# TM4C129ENCPDT register map
File version: 1.0
CPU: CORTEX_M4 1.0, other endian, MPU, FPU, 3 interrupt priority bits
Registers are 32-bit, read-write, reset 0x0 unless marked. A register's access mark holds for its fields unless they carry their own. Offsets are from the block's base; [hi:lo] are bit positions.

## TIMER0 — Timer register offsets
Base 0x40030000
Same registers: TIMER1 0x40031000, TIMER2 0x40032000, TIMER3 0x40033000, TIMER4 0x40034000, TIMER5 0x40035000, TIMER6 0x400E0000, TIMER7 0x400E1000
0x00 TIMER_CFG — GPTM Configuration
  [2:0] TIMER_CFG — [2:0] GPTM Configuration
    0=TIMER_CFG_32_BIT_TIMER (For a 16/32-bit timer, this value selects the 32-bit timer configuration); 1=TIMER_CFG_32_BIT_RTC (For a 16/32-bit timer, this value selects the 32-bit real-time clock (RTC) counter configuration); 4=TIMER_CFG_16_BIT (For a 16/32-bit timer, this value selects the 16-bit timer configuration)
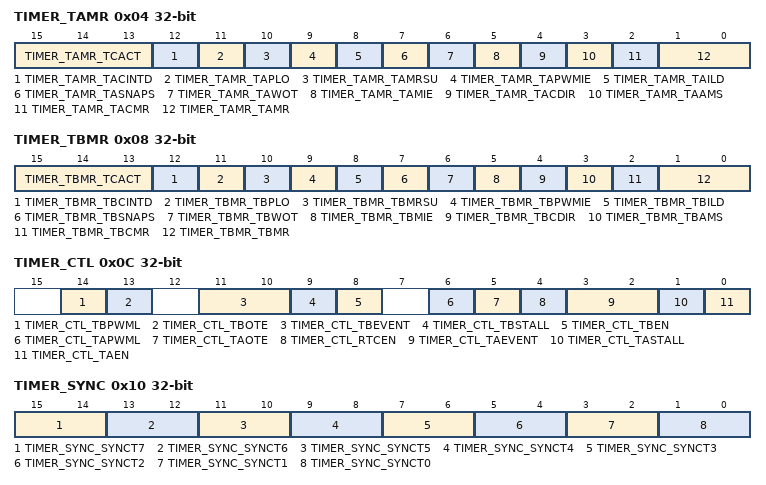
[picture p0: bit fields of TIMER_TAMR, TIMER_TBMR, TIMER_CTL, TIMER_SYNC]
0x04 TIMER_TAMR — GPTM Timer A Mode
  [15:13] TIMER_TAMR_TCACT — [15:13] Timer Compare Action Select
    0=TIMER_TAMR_TCACT_NONE (Disable compare operations); 0x2000=TIMER_TAMR_TCACT_TOGGLE (Toggle State on Time-Out); 0x4000=TIMER_TAMR_TCACT_CLRTO (Clear CCP on Time-Out); 0x6000=TIMER_TAMR_TCACT_SETTO (Set CCP on Time-Out); 0x8000=TIMER_TAMR_TCACT_SETTOGTO (Set CCP immediately and toggle on Time-Out); 0xA000=TIMER_TAMR_TCACT_CLRTOGTO (Clear CCP immediately and toggle on Time-Out); 0xC000=TIMER_TAMR_TCACT_SETCLRTO (Set CCP immediately and clear on Time-Out); 0xE000=TIMER_TAMR_TCACT_CLRSETTO (Clear CCP immediately and set on Time-Out)
  [12] TIMER_TAMR_TACINTD — [12:12] One-shot/Periodic Interrupt Disable
  [11] TIMER_TAMR_TAPLO — [11:11] GPTM Timer A PWM Legacy Operation
  [10] TIMER_TAMR_TAMRSU — [10:10] GPTM Timer A Match Register Update
  [9] TIMER_TAMR_TAPWMIE — [9:9] GPTM Timer A PWM Interrupt Enable
  [8] TIMER_TAMR_TAILD — [8:8] GPTM Timer A Interval Load Write
  [7] TIMER_TAMR_TASNAPS — [7:7] GPTM Timer A Snap-Shot Mode
  [6] TIMER_TAMR_TAWOT — [6:6] GPTM Timer A Wait-on-Trigger
  [5] TIMER_TAMR_TAMIE — [5:5] GPTM Timer A Match Interrupt Enable
  [4] TIMER_TAMR_TACDIR — [4:4] GPTM Timer A Count Direction
  [3] TIMER_TAMR_TAAMS — [3:3] GPTM Timer A Alternate Mode Select
  [2] TIMER_TAMR_TACMR — [2:2] GPTM Timer A Capture Mode
  [1:0] TIMER_TAMR_TAMR — [1:0] GPTM Timer A Mode
    1=TIMER_TAMR_TAMR_1_SHOT (One-Shot Timer mode); 2=TIMER_TAMR_TAMR_PERIOD (Periodic Timer mode); 3=TIMER_TAMR_TAMR_CAP (Capture mode)
0x08 TIMER_TBMR — GPTM Timer B Mode
  [15:13] TIMER_TBMR_TCACT — [15:13] Timer Compare Action Select
    0=TIMER_TBMR_TCACT_NONE (Disable compare operations); 0x2000=TIMER_TBMR_TCACT_TOGGLE (Toggle State on Time-Out); 0x4000=TIMER_TBMR_TCACT_CLRTO (Clear CCP on Time-Out); 0x6000=TIMER_TBMR_TCACT_SETTO (Set CCP on Time-Out); 0x8000=TIMER_TBMR_TCACT_SETTOGTO (Set CCP immediately and toggle on Time-Out); 0xA000=TIMER_TBMR_TCACT_CLRTOGTO (Clear CCP immediately and toggle on Time-Out); 0xC000=TIMER_TBMR_TCACT_SETCLRTO (Set CCP immediately and clear on Time-Out); 0xE000=TIMER_TBMR_TCACT_CLRSETTO (Clear CCP immediately and set on Time-Out)
  [12] TIMER_TBMR_TBCINTD — [12:12] One-Shot/Periodic Interrupt Disable
  [11] TIMER_TBMR_TBPLO — [11:11] GPTM Timer B PWM Legacy Operation
  [10] TIMER_TBMR_TBMRSU — [10:10] GPTM Timer B Match Register Update
  [9] TIMER_TBMR_TBPWMIE — [9:9] GPTM Timer B PWM Interrupt Enable
  [8] TIMER_TBMR_TBILD — [8:8] GPTM Timer B Interval Load Write
  [7] TIMER_TBMR_TBSNAPS — [7:7] GPTM Timer B Snap-Shot Mode
  [6] TIMER_TBMR_TBWOT — [6:6] GPTM Timer B Wait-on-Trigger
  [5] TIMER_TBMR_TBMIE — [5:5] GPTM Timer B Match Interrupt Enable
  [4] TIMER_TBMR_TBCDIR — [4:4] GPTM Timer B Count Direction
  [3] TIMER_TBMR_TBAMS — [3:3] GPTM Timer B Alternate Mode Select
  [2] TIMER_TBMR_TBCMR — [2:2] GPTM Timer B Capture Mode
  [1:0] TIMER_TBMR_TBMR — [1:0] GPTM Timer B Mode
    1=TIMER_TBMR_TBMR_1_SHOT (One-Shot Timer mode); 2=TIMER_TBMR_TBMR_PERIOD (Periodic Timer mode); 3=TIMER_TBMR_TBMR_CAP (Capture mode)
0x0C TIMER_CTL — GPTM Control
  [14] TIMER_CTL_TBPWML — [14:14] GPTM Timer B PWM Output Level
  [13] TIMER_CTL_TBOTE — [13:13] GPTM Timer B Output Trigger Enable
  [11:10] TIMER_CTL_TBEVENT — [11:10] GPTM Timer B Event Mode
    0=TIMER_CTL_TBEVENT_POS (Positive edge); 0x400=TIMER_CTL_TBEVENT_NEG (Negative edge); 0xC00=TIMER_CTL_TBEVENT_BOTH (Both edges)
  [9] TIMER_CTL_TBSTALL — [9:9] GPTM Timer B Stall Enable
  [8] TIMER_CTL_TBEN — [8:8] GPTM Timer B Enable
  [6] TIMER_CTL_TAPWML — [6:6] GPTM Timer A PWM Output Level
  [5] TIMER_CTL_TAOTE — [5:5] GPTM Timer A Output Trigger Enable
  [4] TIMER_CTL_RTCEN — [4:4] GPTM RTC Stall Enable
  [3:2] TIMER_CTL_TAEVENT — [3:2] GPTM Timer A Event Mode
    0=TIMER_CTL_TAEVENT_POS (Positive edge); 4=TIMER_CTL_TAEVENT_NEG (Negative edge); 12=TIMER_CTL_TAEVENT_BOTH (Both edges)
  [1] TIMER_CTL_TASTALL — [1:1] GPTM Timer A Stall Enable
  [0] TIMER_CTL_TAEN — [0:0] GPTM Timer A Enable
0x10 TIMER_SYNC — GPTM Synchronize
  [15:14] TIMER_SYNC_SYNCT7 — [15:14] Synchronize GPTM Timer 7
    0=TIMER_SYNC_SYNCT7_NONE (GPT7 is not affected); 0x4000=TIMER_SYNC_SYNCT7_TA (A timeout event for Timer A of GPTM7 is triggered); 0x8000=TIMER_SYNC_SYNCT7_TB (A timeout event for Timer B of GPTM7 is triggered); 0xC000=TIMER_SYNC_SYNCT7_TATB (A timeout event for both Timer A and Timer B of GPTM7 is triggered)
  [13:12] TIMER_SYNC_SYNCT6 — [13:12] Synchronize GPTM Timer 6
    0=TIMER_SYNC_SYNCT6_NONE (GPTM6 is not affected); 0x1000=TIMER_SYNC_SYNCT6_TA (A timeout event for Timer A of GPTM6 is triggered); 0x2000=TIMER_SYNC_SYNCT6_TB (A timeout event for Timer B of GPTM6 is triggered); 0x3000=TIMER_SYNC_SYNCT6_TATB (A timeout event for both Timer A and Timer B of GPTM6 is triggered)
  [11:10] TIMER_SYNC_SYNCT5 — [11:10] Synchronize GPTM Timer 5
    0=TIMER_SYNC_SYNCT5_NONE (GPTM5 is not affected); 0x400=TIMER_SYNC_SYNCT5_TA (A timeout event for Timer A of GPTM5 is triggered); 0x800=TIMER_SYNC_SYNCT5_TB (A timeout event for Timer B of GPTM5 is triggered); 0xC00=TIMER_SYNC_SYNCT5_TATB (A timeout event for both Timer A and Timer B of GPTM5 is triggered)
  [9:8] TIMER_SYNC_SYNCT4 — [9:8] Synchronize GPTM Timer 4
    0=TIMER_SYNC_SYNCT4_NONE (GPTM4 is not affected); 0x100=TIMER_SYNC_SYNCT4_TA (A timeout event for Timer A of GPTM4 is triggered); 0x200=TIMER_SYNC_SYNCT4_TB (A timeout event for Timer B of GPTM4 is triggered); 0x300=TIMER_SYNC_SYNCT4_TATB (A timeout event for both Timer A and Timer B of GPTM4 is triggered)
  [7:6] TIMER_SYNC_SYNCT3 — [7:6] Synchronize GPTM Timer 3
    0=TIMER_SYNC_SYNCT3_NONE (GPTM3 is not affected); 64=TIMER_SYNC_SYNCT3_TA (A timeout event for Timer A of GPTM3 is triggered); 128=TIMER_SYNC_SYNCT3_TB (A timeout event for Timer B of GPTM3 is triggered); 192=TIMER_SYNC_SYNCT3_TATB (A timeout event for both Timer A and Timer B of GPTM3 is triggered)
  [5:4] TIMER_SYNC_SYNCT2 — [5:4] Synchronize GPTM Timer 2
    0=TIMER_SYNC_SYNCT2_NONE (GPTM2 is not affected); 16=TIMER_SYNC_SYNCT2_TA (A timeout event for Timer A of GPTM2 is triggered); 32=TIMER_SYNC_SYNCT2_TB (A timeout event for Timer B of GPTM2 is triggered); 48=TIMER_SYNC_SYNCT2_TATB (A timeout event for both Timer A and Timer B of GPTM2 is triggered)
  [3:2] TIMER_SYNC_SYNCT1 — [3:2] Synchronize GPTM Timer 1
    0=TIMER_SYNC_SYNCT1_NONE (GPTM1 is not affected); 4=TIMER_SYNC_SYNCT1_TA (A timeout event for Timer A of GPTM1 is triggered); 8=TIMER_SYNC_SYNCT1_TB (A timeout event for Timer B of GPTM1 is triggered); 12=TIMER_SYNC_SYNCT1_TATB (A timeout event for both Timer A and Timer B of GPTM1 is triggered)
  [1:0] TIMER_SYNC_SYNCT0 — [1:0] Synchronize GPTM Timer 0
    0=TIMER_SYNC_SYNCT0_NONE (GPTM0 is not affected); 1=TIMER_SYNC_SYNCT0_TA (A timeout event for Timer A of GPTM0 is triggered); 2=TIMER_SYNC_SYNCT0_TB (A timeout event for Timer B of GPTM0 is triggered); 3=TIMER_SYNC_SYNCT0_TATB (A timeout event for both Timer A and Timer B of GPTM0 is triggered)
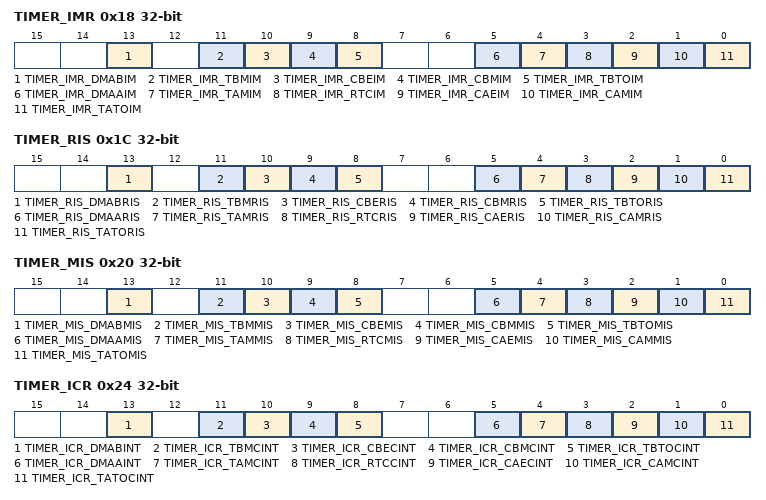
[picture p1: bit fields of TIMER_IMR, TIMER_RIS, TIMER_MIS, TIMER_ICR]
0x18 TIMER_IMR — GPTM Interrupt Mask
  [13] TIMER_IMR_DMABIM — [13:13] GPTM Timer B DMA Done Interrupt Mask
  [11] TIMER_IMR_TBMIM — [11:11] GPTM Timer B Match Interrupt Mask
  [10] TIMER_IMR_CBEIM — [10:10] GPTM Timer B Capture Mode Event Interrupt Mask
  [9] TIMER_IMR_CBMIM — [9:9] GPTM Timer B Capture Mode Match Interrupt Mask
  [8] TIMER_IMR_TBTOIM — [8:8] GPTM Timer B Time-Out Interrupt Mask
  [5] TIMER_IMR_DMAAIM — [5:5] GPTM Timer A DMA Done Interrupt Mask
  [4] TIMER_IMR_TAMIM — [4:4] GPTM Timer A Match Interrupt Mask
  [3] TIMER_IMR_RTCIM — [3:3] GPTM RTC Interrupt Mask
  [2] TIMER_IMR_CAEIM — [2:2] GPTM Timer A Capture Mode Event Interrupt Mask
  [1] TIMER_IMR_CAMIM — [1:1] GPTM Timer A Capture Mode Match Interrupt Mask
  [0] TIMER_IMR_TATOIM — [0:0] GPTM Timer A Time-Out Interrupt Mask
0x1C TIMER_RIS — GPTM Raw Interrupt Status
  [13] TIMER_RIS_DMABRIS — [13:13] GPTM Timer B DMA Done Raw Interrupt Status
  [11] TIMER_RIS_TBMRIS — [11:11] GPTM Timer B Match Raw Interrupt
  [10] TIMER_RIS_CBERIS — [10:10] GPTM Timer B Capture Mode Event Raw Interrupt
  [9] TIMER_RIS_CBMRIS — [9:9] GPTM Timer B Capture Mode Match Raw Interrupt
  [8] TIMER_RIS_TBTORIS — [8:8] GPTM Timer B Time-Out Raw Interrupt
  [5] TIMER_RIS_DMAARIS — [5:5] GPTM Timer A DMA Done Raw Interrupt Status
  [4] TIMER_RIS_TAMRIS — [4:4] GPTM Timer A Match Raw Interrupt
  [3] TIMER_RIS_RTCRIS — [3:3] GPTM RTC Raw Interrupt
  [2] TIMER_RIS_CAERIS — [2:2] GPTM Timer A Capture Mode Event Raw Interrupt
  [1] TIMER_RIS_CAMRIS — [1:1] GPTM Timer A Capture Mode Match Raw Interrupt
  [0] TIMER_RIS_TATORIS — [0:0] GPTM Timer A Time-Out Raw Interrupt
0x20 TIMER_MIS — GPTM Masked Interrupt Status
  [13] TIMER_MIS_DMABMIS — [13:13] GPTM Timer B DMA Done Masked Interrupt
  [11] TIMER_MIS_TBMMIS — [11:11] GPTM Timer B Match Masked Interrupt
  [10] TIMER_MIS_CBEMIS — [10:10] GPTM Timer B Capture Mode Event Masked Interrupt
  [9] TIMER_MIS_CBMMIS — [9:9] GPTM Timer B Capture Mode Match Masked Interrupt
  [8] TIMER_MIS_TBTOMIS — [8:8] GPTM Timer B Time-Out Masked Interrupt
  [5] TIMER_MIS_DMAAMIS — [5:5] GPTM Timer A DMA Done Masked Interrupt
  [4] TIMER_MIS_TAMMIS — [4:4] GPTM Timer A Match Masked Interrupt
  [3] TIMER_MIS_RTCMIS — [3:3] GPTM RTC Masked Interrupt
  [2] TIMER_MIS_CAEMIS — [2:2] GPTM Timer A Capture Mode Event Masked Interrupt
  [1] TIMER_MIS_CAMMIS — [1:1] GPTM Timer A Capture Mode Match Masked Interrupt
  [0] TIMER_MIS_TATOMIS — [0:0] GPTM Timer A Time-Out Masked Interrupt
0x24 TIMER_ICR — GPTM Interrupt Clear
  [13] TIMER_ICR_DMABINT — [13:13] GPTM Timer B DMA Done Interrupt Clear
  [11] TIMER_ICR_TBMCINT — [11:11] GPTM Timer B Match Interrupt Clear
  [10] TIMER_ICR_CBECINT — [10:10] GPTM Timer B Capture Mode Event Interrupt Clear
  [9] TIMER_ICR_CBMCINT — [9:9] GPTM Timer B Capture Mode Match Interrupt Clear
  [8] TIMER_ICR_TBTOCINT — [8:8] GPTM Timer B Time-Out Interrupt Clear
  [5] TIMER_ICR_DMAAINT — [5:5] GPTM Timer A DMA Done Interrupt Clear
  [4] TIMER_ICR_TAMCINT — [4:4] GPTM Timer A Match Interrupt Clear
  [3] TIMER_ICR_RTCCINT — [3:3] GPTM RTC Interrupt Clear
  [2] TIMER_ICR_CAECINT — [2:2] GPTM Timer A Capture Mode Event Interrupt Clear
  [1] TIMER_ICR_CAMCINT — [1:1] GPTM Timer A Capture Mode Match Interrupt Clear
  [0] TIMER_ICR_TATOCINT — [0:0] GPTM Timer A Time-Out Raw Interrupt
0x28 TIMER_TAILR — GPTM Timer A Interval Load
  [31:0] TIMER_TAILR — [31:0] GPTM Timer A Interval Load Register
0x2C TIMER_TBILR — GPTM Timer B Interval Load
  [31:0] TIMER_TBILR — [31:0] GPTM Timer B Interval Load Register
0x30 TIMER_TAMATCHR — GPTM Timer A Match
  [31:0] TIMER_TAMATCHR_TAMR — [31:0] GPTM Timer A Match Register
0x34 TIMER_TBMATCHR — GPTM Timer B Match
  [31:0] TIMER_TBMATCHR_TBMR — [31:0] GPTM Timer B Match Register
0x38 TIMER_TAPR — GPTM Timer A Prescale
  [7:0] TIMER_TAPR_TAPSR — [7:0] GPTM Timer A Prescale
0x3C TIMER_TBPR — GPTM Timer B Prescale
  [7:0] TIMER_TBPR_TBPSR — [7:0] GPTM Timer B Prescale
0x40 TIMER_TAPMR — GPTM TimerA Prescale Match
  [7:0] TIMER_TAPMR_TAPSMR — [7:0] GPTM TimerA Prescale Match
0x44 TIMER_TBPMR — GPTM TimerB Prescale Match
  [7:0] TIMER_TBPMR_TBPSMR — [7:0] GPTM TimerB Prescale Match
0x48 TIMER_TAR — GPTM Timer A
  [31:0] TIMER_TAR — [31:0] GPTM Timer A Register
0x4C TIMER_TBR — GPTM Timer B
  [31:0] TIMER_TBR — [31:0] GPTM Timer B Register
0x50 TIMER_TAV — GPTM Timer A Value
  [31:0] TIMER_TAV — [31:0] GPTM Timer A Value
0x54 TIMER_TBV — GPTM Timer B Value
  [31:0] TIMER_TBV — [31:0] GPTM Timer B Value
0x58 TIMER_RTCPD — GPTM RTC Predivide
  [15:0] TIMER_RTCPD_RTCPD — [15:0] RTC Predivide Counter Value
0x5C TIMER_TAPS — GPTM Timer A Prescale Snapshot
  [15:0] TIMER_TAPS_PSS — [15:0] GPTM Timer A Prescaler Snapshot
0x60 TIMER_TBPS — GPTM Timer B Prescale Snapshot
  [15:0] TIMER_TBPS_PSS — [15:0] GPTM Timer A Prescaler Value
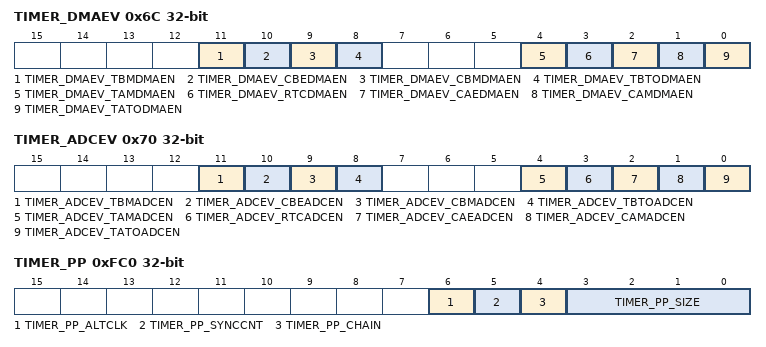
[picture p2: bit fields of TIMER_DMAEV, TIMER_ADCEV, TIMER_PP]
0x6C TIMER_DMAEV — GPTM DMA Event
  [11] TIMER_DMAEV_TBMDMAEN — [11:11] GPTM B Mode Match Event DMA Trigger Enable
  [10] TIMER_DMAEV_CBEDMAEN — [10:10] GPTM B Capture Event DMA Trigger Enable
  [9] TIMER_DMAEV_CBMDMAEN — [9:9] GPTM B Capture Match Event DMA Trigger Enable
  [8] TIMER_DMAEV_TBTODMAEN — [8:8] GPTM B Time-Out Event DMA Trigger Enable
  [4] TIMER_DMAEV_TAMDMAEN — [4:4] GPTM A Mode Match Event DMA Trigger Enable
  [3] TIMER_DMAEV_RTCDMAEN — [3:3] GPTM A RTC Match Event DMA Trigger Enable
  [2] TIMER_DMAEV_CAEDMAEN — [2:2] GPTM A Capture Event DMA Trigger Enable
  [1] TIMER_DMAEV_CAMDMAEN — [1:1] GPTM A Capture Match Event DMA Trigger Enable
  [0] TIMER_DMAEV_TATODMAEN — [0:0] GPTM A Time-Out Event DMA Trigger Enable
0x70 TIMER_ADCEV — GPTM ADC Event
  [11] TIMER_ADCEV_TBMADCEN — [11:11] GPTM B Mode Match Event ADC Trigger Enable
  [10] TIMER_ADCEV_CBEADCEN — [10:10] GPTM B Capture Event ADC Trigger Enable
  [9] TIMER_ADCEV_CBMADCEN — [9:9] GPTM B Capture Match Event ADC Trigger Enable
  [8] TIMER_ADCEV_TBTOADCEN — [8:8] GPTM B Time-Out Event ADC Trigger Enable
  [4] TIMER_ADCEV_TAMADCEN — [4:4] GPTM A Mode Match Event ADC Trigger Enable
  [3] TIMER_ADCEV_RTCADCEN — [3:3] GPTM RTC Match Event ADC Trigger Enable
  [2] TIMER_ADCEV_CAEADCEN — [2:2] GPTM A Capture Event ADC Trigger Enable
  [1] TIMER_ADCEV_CAMADCEN — [1:1] GPTM A Capture Match Event ADC Trigger Enable
  [0] TIMER_ADCEV_TATOADCEN — [0:0] GPTM A Time-Out Event ADC Trigger Enable
0xFC0 TIMER_PP — GPTM Peripheral Properties
  [6] TIMER_PP_ALTCLK — [6:6] Alternate Clock Source
  [5] TIMER_PP_SYNCCNT — [5:5] Synchronize Start
  [4] TIMER_PP_CHAIN — [4:4] Chain with Other Timers
  [3:0] TIMER_PP_SIZE — [3:0] Count Size
    0=Timer A and Timer B counters are 16 bits each with an 8-bit prescale counter; 1=Timer A and Timer B counters are 32 bits each with a 16-bit prescale counter
0xFC8 TIMER_CC — GPTM Clock Configuration
  [0] TIMER_CC_ALTCLK — [0:0] Alternate Clock Source
